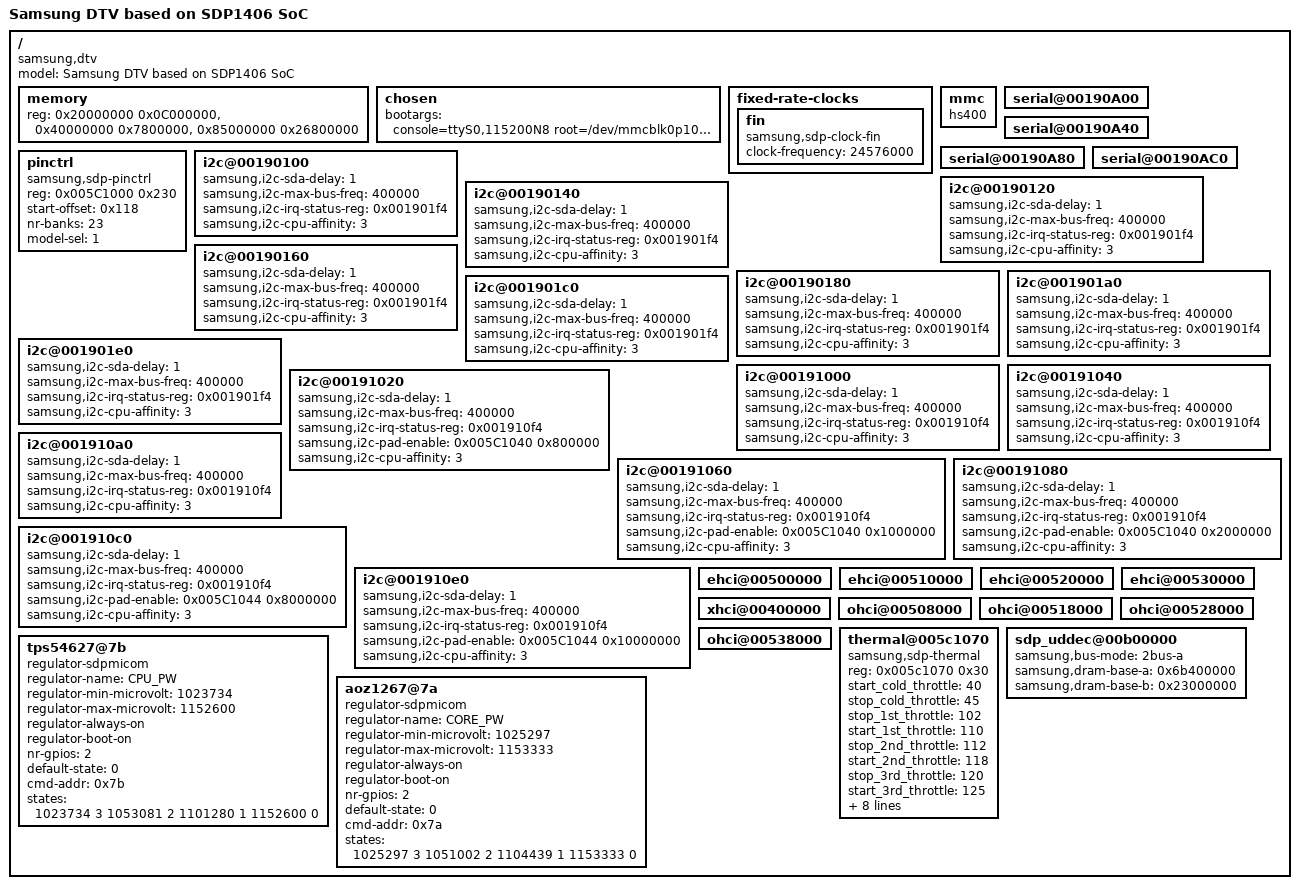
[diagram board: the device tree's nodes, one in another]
/*
 * Copyright (C) 2014 Samsung Electronics Co.Ltd
 *
 * This program is free software; you can redistribute it and/or modify
 * it under the terms of the GNU General Public License version 2 as
 * published by the Free Software Foundation.
 */

/dts-v1/;
/include/ "sdp1406.dtsi"

/ {
	model = "Samsung DTV based on SDP1406 SoC";
	compatible = "samsung,dtv", "samsung,sdp1406";

	memory {
		device_type = "memory";
		reg =  <0x20000000 0x0C000000>, <0x40000000 0x7800000>, <0x85000000 0x26800000>;
	};
	/*in the below chosen, between mmcblk0p8 and SELP_ENABLE must more than 1 space.because 2nd booting will change mmcblk0p8 to mmcblk0p11 */
	chosen {
		bootargs = "console=ttyS0,115200N8 root=/dev/mmcblk0p10  SELP_ENABLE=00000000 rootfstype=squashfs rootwait no_console_suspend earlyprintk sdp_sparsemem vmalloc=700M";
	};

	fixed-rate-clocks {
		fin {
			compatible = "samsung,sdp-clock-fin";
			clock-frequency = <24576000>;
		};
	};

	mmc {
//		hs200;
//		hs200-tuning;
		hs400;
	};

	serial@00190A00 {
		status = "okay";
	};

	serial@00190A40 {
		status = "okay";
	};

	serial@00190A80 {
		status = "okay";
	};

	serial@00190AC0 {
		status = "okay";
	};

	pinctrl{
		compatible = "samsung,sdp-pinctrl";
		reg = <0x005C1000 0x230>;
		start-offset = <0x118>;
		nr-banks = <23>;	
		model-sel = <1>;	
	};

	i2c@00190100 {
		status = "okay";
		samsung,i2c-sda-delay = <1>;
		samsung,i2c-max-bus-freq = <400000>;
		samsung,i2c-irq-status-reg = <0x001901f4>;
		samsung,i2c-cpu-affinity = <3>;
	};

	i2c@00190120 {
		status = "okay";
		samsung,i2c-sda-delay = <1>;
		samsung,i2c-max-bus-freq = <400000>;
		samsung,i2c-irq-status-reg = <0x001901f4>;
		samsung,i2c-cpu-affinity = <3>;
	};

	i2c@00190140 { 
		status = "okay";
		samsung,i2c-sda-delay = <1>;
		samsung,i2c-max-bus-freq = <400000>;
		samsung,i2c-irq-status-reg = <0x001901f4>;
		samsung,i2c-cpu-affinity = <3>;
	};

	i2c@00190160 {
		status = "okay";
		samsung,i2c-sda-delay = <1>;
		samsung,i2c-max-bus-freq = <400000>;
		samsung,i2c-irq-status-reg = <0x001901f4>;
		samsung,i2c-cpu-affinity = <3>;
	};

	i2c@00190180 {
		status = "okay";
		samsung,i2c-sda-delay = <1>;
		samsung,i2c-max-bus-freq = <400000>;
		samsung,i2c-irq-status-reg = <0x001901f4>;
		samsung,i2c-cpu-affinity = <3>;
	};

	i2c@001901a0 {
		status = "okay";
		samsung,i2c-sda-delay = <1>;
		samsung,i2c-max-bus-freq = <400000>;
		samsung,i2c-irq-status-reg = <0x001901f4>;
		samsung,i2c-cpu-affinity = <3>;
	};

	i2c@001901c0 {
		status = "okay";
		samsung,i2c-sda-delay = <1>;
		samsung,i2c-max-bus-freq = <400000>;
		samsung,i2c-irq-status-reg = <0x001901f4>;
		samsung,i2c-cpu-affinity = <3>;
	};

	i2c@001901e0 {
		status = "okay";
		samsung,i2c-sda-delay = <1>;
		samsung,i2c-max-bus-freq = <400000>;
		samsung,i2c-irq-status-reg = <0x001901f4>;
		samsung,i2c-cpu-affinity = <3>;
	};

	i2c@00191000 {
		status = "okay";
		samsung,i2c-sda-delay = <1>;
		samsung,i2c-max-bus-freq = <400000>;
		samsung,i2c-irq-status-reg = <0x001910f4>;
		samsung,i2c-cpu-affinity = <3>;
	};

	i2c@00191020 {
		status = "okay";
		samsung,i2c-sda-delay = <1>;
		samsung,i2c-max-bus-freq = <400000>;
		samsung,i2c-irq-status-reg = <0x001910f4>;
		samsung,i2c-pad-enable = <0x005C1040 0x800000>;
		samsung,i2c-cpu-affinity = <3>;
	};

	i2c@00191040 { 
		status = "okay";
		samsung,i2c-sda-delay = <1>;
		samsung,i2c-max-bus-freq = <400000>;
		samsung,i2c-irq-status-reg = <0x001910f4>;
	//	samsung,i2c-pad-enable = <0x10030000 0x80000000>;// Mux HS
		samsung,i2c-cpu-affinity = <3>;
	};

	i2c@00191060 {
		status = "okay";
		samsung,i2c-sda-delay = <1>;
		samsung,i2c-max-bus-freq = <400000>;
		samsung,i2c-irq-status-reg = <0x001910f4>;
		samsung,i2c-pad-enable = <0x005C1040 0x1000000>;
		samsung,i2c-cpu-affinity = <3>;
	};

	i2c@00191080 {
		status = "okay";
		samsung,i2c-sda-delay = <1>;
		samsung,i2c-max-bus-freq = <400000>;
		samsung,i2c-irq-status-reg = <0x001910f4>;
		samsung,i2c-pad-enable = <0x005C1040 0x2000000>;
		samsung,i2c-cpu-affinity = <3>;
	};

	i2c@001910a0 {
		status = "okay";
		samsung,i2c-sda-delay = <1>;
		samsung,i2c-max-bus-freq = <400000>;
		samsung,i2c-irq-status-reg = <0x001910f4>;
		samsung,i2c-cpu-affinity = <3>;
	};

	i2c@001910c0 {
		status = "okay";
		samsung,i2c-sda-delay = <1>;
		samsung,i2c-max-bus-freq = <400000>;
		samsung,i2c-irq-status-reg = <0x001910f4>;
		samsung,i2c-pad-enable = <0x005C1044 0x8000000>;
		samsung,i2c-cpu-affinity = <3>;
	};

	i2c@001910e0 {
		status = "okay";
		samsung,i2c-sda-delay = <1>;
		samsung,i2c-max-bus-freq = <400000>;
		samsung,i2c-irq-status-reg = <0x001910f4>;
		samsung,i2c-pad-enable = <0x005C1044 0x10000000>;
		samsung,i2c-cpu-affinity = <3>;

	};

	ehci@00500000 {
		status = "okay";
	/*	samsung,sw-reset = <0x005C0000 0xE4 0x1000>;
		samsung,ehci-gpr_reg = <0x00540000 0x04 0x7000>;
		samsung,ehci-gpr_reg1 = <0x00540000 0x0C 0x100C0>;
		samsung,sw-reset-release = <0x005C0000 0xE4 0x1000>;*/
	};

        ehci@00510000 {
		status = "okay";
	/*	samsung,sw-reset = <0x005C0000 0xE4 0x2000>;
		samsung,ehci-gpr_reg = <0x00540000 0x18 0x7000>;
		samsung,ehci-gpr_reg1 = <0x00540000 0x20 0x100C0>;
		samsung,sw-reset-release = <0x005C0000 0xE4 0x2000>;*/
	};
	
	ehci@00520000 {
		status = "okay";
	/*	samsung,sw-reset = <0x005C0000 0xE4 0x4000>;
		samsung,ehci-gpr_reg = <0x00540000 0x2c 0x7000>;
		samsung,ehci-gpr_reg1 = <0x00540000 0x34 0x100C0>;
		samsung,sw-reset-release = <0x005C0000 0xE4 0x4000>;*/
	};

	ehci@00530000 {
		status = "okay";
	/*	samsung,sw-reset = <0x005C0000 0xE4 0x8000>;
		samsung,ehci-gpr_reg = <0x00540000 0x40 0x7000>;
		samsung,ehci-gpr_reg1 = <0x00540000 0x48 0x100C0>;
		samsung,sw-reset-release = <0x005C0000 0xE4 0x8000>;*/
	};

	
	xhci@00400000 {
		status = "okay";
	};


	ohci@00508000 {
		status = "okay";
	};

	ohci@00518000 {
		status = "okay";
	};

	ohci@00528000 {
		status = "okay";
	};

	ohci@00538000 {
		status = "okay";
	};

	thermal@005c1070 {
		status = "okay";
		compatible = "samsung,sdp-thermal";

		reg = <0x005c1070 0x30>;

		start_cold_throttle	= <40>;
		stop_cold_throttle	= <45>;
		stop_1st_throttle	= <102>;
		start_1st_throttle	= <110>;
		stop_2nd_throttle	= <112>;
		start_2nd_throttle	= <118>;
		stop_3rd_throttle	= <120>;
		start_3rd_throttle	= <125>;
		start_3rd_hotplug	= <130>;

		cpu_limit_1st_throttle	= <1000000>;
		cpu_limit_2nd_throttle	= <700000>;
		cpu_limit_3rd_throttle	= <100000>;

		gpu_limit_1st_throttle	= <185000>;
		gpu_limit_2nd_throttle	= <185000>;
		gpu_limit_3rd_throttle	= <185000>;

		log_file_path = "/mtd_rwarea/ThermalThrottle.txt";
	};

	sdp_uddec@00b00000 {
		samsung,bus-mode = "2bus-a";
		samsung,dram-base-a = <0x6b400000>;
		samsung,dram-base-b = <0x23000000>;
	};

	tps54627@7b {
		compatible = "regulator-sdpmicom";

		regulator-name = "CPU_PW";
		regulator-min-microvolt = <1023734>;
		regulator-max-microvolt = <1152600>;
		regulator-always-on;
		regulator-boot-on;

		nr-gpios = <2>;
		default-state = <0>;
		cmd-addr = <0x7b>;
		states = <1023734 3
			1053081 2
			1101280 1
			1152600 0>;	
	};

	aoz1267@7a {
		compatible = "regulator-sdpmicom";

		regulator-name = "CORE_PW";
		regulator-min-microvolt = <1025297>;
		regulator-max-microvolt = <1153333>;
		regulator-always-on;
		regulator-boot-on;

		nr-gpios = <2>;
		default-state = <0>;
		cmd-addr = <0x7a>;
		states = <1025297 3
			1051002 2
			1104439 1
			1153333 0>;	
	};
};
